VERSION ""

NS_ :

BS_:

BU_:

BO_ 3221225472 VECTOR__INDEPENDENT_SIG_MSG: 0 Vector__XXX
 SG_ reserved : 9|7@1+ (1,0) [0|0] "" Vector__XXX
 SG_ velocity_valid : 97|1@1+ (1,0) [0|0] "" Vector__XXX
 SG_ position_valid : 96|1@1+ (1,0) [0|0] "" Vector__XXX
 SG_ throttle : 64|32@1- (1,0) [0|0] "Percent" Vector__XXX
 SG_ velocity : 32|32@1- (1,0) [0|0] "Rotations per Second" Vector__XXX

BO_ 256 BMCModeCmd: 2 Vector__XXX
 SG_ mode : 0|8@1+ (1,0) [0|0] "" Vector__XXX
 SG_ enable : 8|1@1+ (1,0) [0|0] "" Vector__XXX

BO_ 272 BMCTargetCmd: 5 Vector__XXX
 SG_ target : 0|32@1- (1,0) [0|0] "" Vector__XXX
 SG_ target_valid : 32|1@1+ (1,0) [0|0] "" Vector__XXX

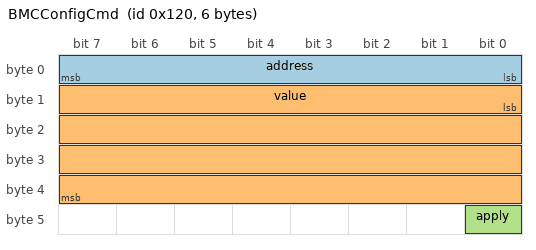
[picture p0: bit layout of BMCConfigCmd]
BO_ 288 BMCConfigCmd: 6 Vector__XXX
 SG_ address : 0|8@1+ (1,0) [0|0] "Memory Address" Vector__XXX
 SG_ value : 8|32@1+ (1,0) [0|0] "" Vector__XXX
 SG_ apply : 40|1@1+ (1,0) [0|0] "" Vector__XXX

BO_ 304 BMCResetCmd: 1 Vector__XXX
 SG_ reset : 0|1@1+ (1,0) [0|0] "" Vector__XXX
 SG_ clear_faults : 1|1@1+ (1,0) [0|0] "" Vector__XXX

BO_ 512 BMCMotorState: 20 Vector__XXX
 SG_ mode : 0|8@1+ (1,0) [0|0] "" Vector__XXX
 SG_ fault_code : 8|8@1+ (1,0) [0|0] "" Vector__XXX
 SG_ position : 16|32@1- (1,0) [0|0] "Radians" Vector__XXX
 SG_ velocity : 48|32@1- (1,0) [0|0] "Radians per Second" Vector__XXX
 SG_ timestamp : 80|16@1+ (1,0) [0|0] "" Vector__XXX
 SG_ limit_a : 96|1@1+ (1,0) [0|0] "" Vector__XXX
 SG_ limit_b : 97|1@1+ (1,0) [0|0] "" Vector__XXX
 SG_ is_stalled : 98|1@1+ (1,0) [0|0] "" Vector__XXX
 SG_ current : 104|32@1- (1,0) [0|0] "" Vector__XXX

BO_ 320 BMCProbe: 4 Vector__XXX
 SG_ data : 0|32@1+ (1,0) [0|0] "" Vector__XXX

BO_ 528 BMCAck: 4 Vector__XXX
 SG_ data : 0|32@1+ (1,0) [0|0] "" Vector__XXX

BA_DEF_ BO_  "CANFD_BRS" ENUM  "0","1";
BA_DEF_  "BusType" STRING ;
BA_DEF_ BO_  "VFrameFormat" ENUM  "StandardCAN","ExtendedCAN","reserved","reserved","reserved","reserved","reserved","reserved","reserved","reserved","reserved","reserved","reserved","reserved","StandardCAN_FD","ExtendedCAN_FD";
BA_DEF_DEF_  "CANFD_BRS" "1";
BA_DEF_DEF_  "BusType" "";
BA_DEF_DEF_  "VFrameFormat" "StandardCAN";
BA_ "BusType" "CAN FD";
BA_ "VFrameFormat" BO_ 256 14;
BA_ "VFrameFormat" BO_ 272 14;
BA_ "VFrameFormat" BO_ 288 14;
BA_ "VFrameFormat" BO_ 304 14;
BA_ "VFrameFormat" BO_ 512 14;
BA_ "VFrameFormat" BO_ 320 14;
BA_ "VFrameFormat" BO_ 528 14;
VAL_ 3221225472 velocity_valid 1 "Valid" 0 "Invalid" ;
VAL_ 3221225472 position_valid 1 "Valid" 0 "Invalid" ;
VAL_ 256 mode 0 "Stopped" 1 "Fault" 5 "Throttle" 6 "Position" 7 "Velocity" ;
VAL_ 256 enable 1 "Enabled" 0 "Disabled" ;
VAL_ 272 target_valid 1 "Valid" 0 "Invalid" ;
VAL_ 304 reset 1 "Enable" 0 "Disable" ;
VAL_ 304 clear_faults 1 "Enable" 0 "Disable" ;
VAL_ 512 mode 0 "Stopped" 1 "Fault" 5 "Throttle" 6 "Position" 7 "Velocity" ;
SIG_VALTYPE_ 3221225472 throttle : 1;
SIG_VALTYPE_ 3221225472 velocity : 1;
SIG_VALTYPE_ 272 target : 1;
SIG_VALTYPE_ 512 position : 1;
SIG_VALTYPE_ 512 velocity : 1;
SIG_VALTYPE_ 512 current : 1;
